# EFR32FG23B021F512IM48 register map
Vendor: Silicon Labs; Series: EFR32; File version: C
CPU: CM33 r0p4, little endian, MPU, FPU, DSP, VTOR, 4 interrupt priority bits, 8 SAU regions
Registers are 32-bit, read-write, reset 0x0 unless marked. A register's access mark holds for its fields unless they carry their own. Offsets are from the block's base; [hi:lo] are bit positions; {n}, {i} and the like mark numbered series; 'fields as' and 'values as' point back to an identical list.

## LESENSE_NS — LESENSE_NS Registers
Base 0x59038000
Same registers: LESENSE_S 0x49038000
0x00 IPVERSION ro reset 0x1
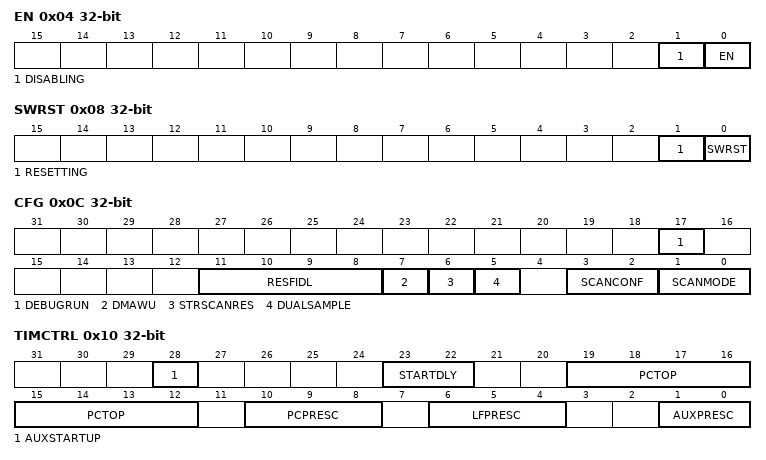
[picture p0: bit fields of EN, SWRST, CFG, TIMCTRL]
0x04 EN — Global Enable of LESENSE functions
  [1] DISABLING ro
  [0] EN — Enable
    0=DISABLE; 1=ENABLE
0x08 SWRST
  [1] RESETTING ro — Software reset busy status
  [0] SWRST wo — Software reset command
0x0C CFG — Configuration Register
  [17] DEBUGRUN — Debug Mode Run Enable
    0=LESENSE can not start new scans in debug mode; 1=LESENSE can start new scans in debug mode
  [11:8] RESFIDL — Result FIFO level
  [7] DMAWU — DMA wake-up from EM2
    0=DISABLE (No DMA wake-up from EM2); 1=ENABLE (DMA wake-up from EM2 when FIFO count is greater or equal to RESFIDL)
  [6] STRSCANRES — Enable storing of SCANRES
  [5] DUALSAMPLE — Enable dual sample mode
  [3:2] SCANCONF — Select scan configuration
    0=DIRMAP (The channel configuration register registers used are directly mapped to the channel number.); 1=INVMAP (The channel configuration registers used are CH[X+8]_CONF for channels 0-7 and CH[X-8]_CONF for channels 8-15.); 2=TOGGLE (The channel configuration registers used toggle between CH[X]_CONF and CH[X+8]_CONF when channel x triggers); 3=DECDEF (The decoder state defines the CONF registers to be used.)
  [1:0] SCANMODE — Configure scan mode
    0=PERIODIC (A new scan is started each time the period counter overflows); 1=ONESHOT (A single scan is performed when START in CMD is set); 2=PRS (Pulse on PRS channel)
0x10 TIMCTRL — Timing Control Register
  [28] AUXSTARTUP — AUX startup config
    0=PREDEMAND (Request oscillator .5 LESENSECLK cycle before sensing starts); 1=ONDEMAND (Request oscillator at sensing time)
  [23:22] STARTDLY — Start delay configuration
  [19:12] PCTOP — Period counter top value
  [10:8] PCPRESC — Period counter prescaling
    0=DIV1 (The period counter clock frequency is LESENSECLK/1); 1=DIV2 (The period counter clock frequency is LESENSECLK/2); 2=DIV4 (The period counter clock frequency is LESENSECLK/4); 3=DIV8 (The period counter clock frequency is LESENSECLK/8); 4=DIV16 (The period counter clock frequency is LESENSECLK/16); 5=DIV32 (The period counter clock frequency is LESENSECLK/32); 6=DIV64 (The period counter clock frequency is LESENSECLK/64); 7=DIV128 (The period counter clock frequency is LESENSECLK/128)
  [6:4] LFPRESC — Prescaling factor for low frequency time
    0=DIV1 (Low frequency timer is clocked with LESENSECLK/1); 1=DIV2 (Low frequency timer is clocked with LESENSECLK/2); 2=DIV4 (Low frequency timer is clocked with LESENSECLK/4); 3=DIV8 (Low frequency timer is clocked with LESENSECLK/8); 4=DIV16 (Low frequency timer is clocked with LESENSECLK/16); 5=DIV32 (Low frequency timer is clocked with LESENSECLK/32); 6=DIV64 (Low frequency timer is clocked with LESENSECLK/64); 7=DIV128 (Low frequency timer is clocked with LESENSECLK/128)
  [1:0] AUXPRESC — Prescaling factor for high frequency tim
    0=DIV1 (High frequency timer is clocked at LESENSEHFCLK/1); 1=DIV2 (High frequency timer is clocked at LESENSEHFCLK/2); 2=DIV4 (High frequency timer is clocked at LESENSEHFCLK/4); 3=DIV8 (High frequency timer is clocked at LESENSEHFCLK/8)
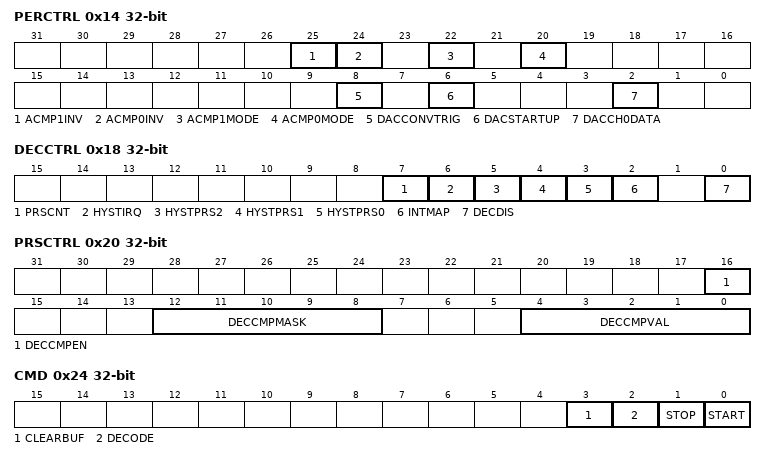
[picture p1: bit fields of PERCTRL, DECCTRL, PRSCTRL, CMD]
0x14 PERCTRL — Peripheral Control Register
  [25] ACMP1INV — Invert analog comparator 1 output
  [24] ACMP0INV — Invert analog comparator 0 output
  [22] ACMP1MODE
    0=MUX (LESENSE controls the POSSEL of ACMP1); 1=MUXTHRES (LESENSE POSSEL and reference divider of ACMP1)
  [20] ACMP0MODE
    0=MUX (LESENSE controls POSSEL of ACMP0); 1=MUXTHRES (LESENSE controls POSSEL and reference divider of ACMP0)
  [8] DACCONVTRIG — DAC conversion trigger configuration
    0=CHANNELSTART (DAC is enabled before every LESENSE channle measurement.); 1=SCANSTART (DAC is only enabled once per scan.)
  [6] DACSTARTUP — DAC startup configuration
    0=FULLCYCLE (DAC is started a full LESENSECLK before sensor interaction starts.); 1=HALFCYCLE (DAC is started half a LESENSECLK cycle before sensor interaction starts.)
  [2] DACCH0DATA — DAC CH0 data selection.
    0=DACDATA (DAC data is defined by CH0DATA in the DAC interface.); 1=THRES (DAC data is defined by THRES in CHx_INTERACT.)
0x18 DECCTRL — Decoder control Register
  [7] PRSCNT — Enable count mode on decoder PRS channel
  [6] HYSTIRQ — Enable decoder hysteresis on interrupt r
  [5] HYSTPRS2 — Enable decoder hysteresis on PRS2 output
  [4] HYSTPRS1 — Enable decoder hysteresis on PRS1 output
  [3] HYSTPRS0 — Enable decoder hysteresis on PRS0 output
  [2] INTMAP — Enable decoder to channel interrupt map
  [0] DECDIS — Disable the decoder
0x1C EVALCTRL — LESENSE evaluation control
  [15:0] WINSIZE — Sliding window and step detection size
0x20 PRSCTRL — PRS control register
  [16] DECCMPEN — Enable PRS output DECCMP
  [12:8] DECCMPMASK — Decoder state compare value mask
  [4:0] DECCMPVAL — Decoder state compare value
0x24 CMD wo — Command Register
  [3] CLEARBUF — Clear result buffer
  [2] DECODE — Start decoder
  [1] STOP — Stop scanning of sensors
  [0] START — Start scanning of sensors.
0x28 CHEN — Channel enable Register
  [15:0] CHEN — Enable scan channel
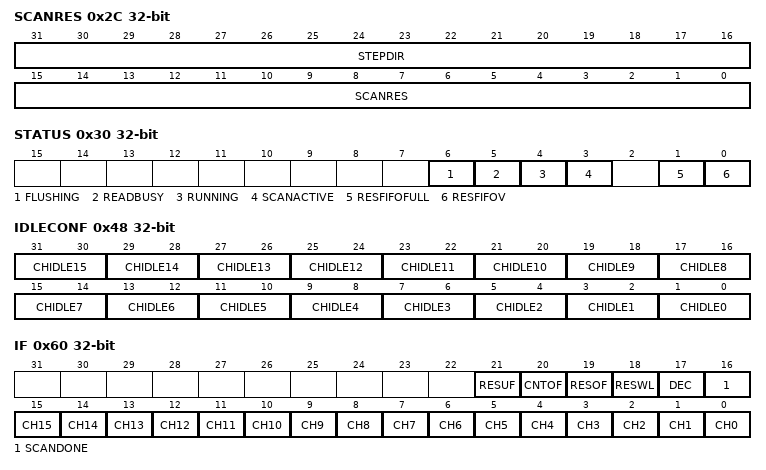
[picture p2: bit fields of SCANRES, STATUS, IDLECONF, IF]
0x2C SCANRES ro — Scan result register
  [31:16] STEPDIR — Direction of previous step detection
  [15:0] SCANRES — Scan results
0x30 STATUS ro
  [6] FLUSHING — FIFO Flushing
  [5] READBUSY — FIFO Read Busy
  [4] RUNNING — LESENSE periodic counter running
  [3] SCANACTIVE — LESENSE scan active
  [1] RESFIFOFULL — Result fifo full
  [0] RESFIFOV — Result fifo valid
0x34 RESCOUNT ro — Result FIFO Count
  [4:0] COUNT — Result Fifo Count
0x38 RESFIFO ro — Result Fifo
  [19:0] BUFDATASRC — Result data and source
0x3C CURCH ro — Current channel index
  [3:0] CURCH — Shows the index of the current channel
0x40 DECSTATE ro — Current decoder state
  [4:0] DECSTATE — Shows the current decoder state
0x44 SENSORSTATE ro — Decoder input register
  [3:0] SENSORSTATE
0x48 IDLECONF — GPIO Idle phase configuration
  [all] fields
    0=DISABLE (Channel output is disabled in idle phase); 1=HIGH (Channel output is high in idle phase); 2=LOW (Channel output is low in idle phase); 3=DAC (Channel output is connected to DAC output in idle phase (CH 0,1,2 only))
  [2n+1:2n] CHIDLE{n} (n=0..15) — Channel IDLE configuration
0x50 SYNCBUSY ro — Synchronization Busy Register
  [0] CMD — Command
0x60 IF — Interrupt Flags
  [21] RESUF — Result Underflow
  [20] CNTOF — Counter Overflow
  [19] RESOF — Result Overflow
  [18] RESWL — Result Watermark Level
  [17] DEC — Decoder
  [16] SCANDONE
  [n] CH{n} (n=0..15) — Channel
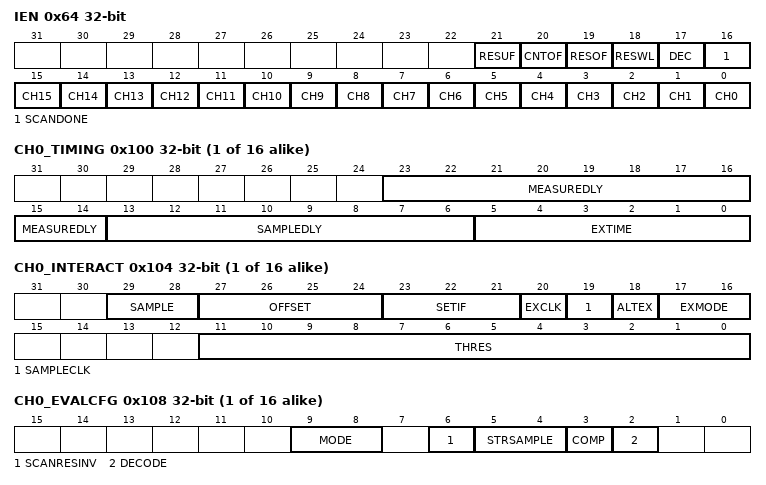
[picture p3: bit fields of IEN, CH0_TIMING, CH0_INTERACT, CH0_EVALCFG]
0x64 IEN — Interrupt Enables
  [21] RESUF — Result Underflow
  [20] CNTOF — Counter Overflow
  [19] RESOF — Result Overflow
  [18] RESWL — Result Watermark Level
  [17] DEC — Decoder
  [16] SCANDONE — Scan Complete
  [n] CH{n} (n=0..15) — Channel
{0x100+0x10*i} CH{i}_TIMING (i=0..15)
  [23:14] MEASUREDLY — Set measure delay
  [13:6] SAMPLEDLY — Set sample delay
  [5:0] EXTIME — Set excitation time
{0x104+0x10*i} CH{i}_INTERACT (i=0..15)
  [29:28] SAMPLE — Sample mode Selection
    0=ACMPCOUNT; 1=ACMP; 2=ADC; 3=ADCDIFF
  [27:24] OFFSET — OFFSET for IADC/ACMP interaction
  [23:21] SETIF — Enable interrupt generation
    0=NONE (No interrupt is generated); 1=LEVEL (Set interrupt flag if the sensor triggers.); 2=POSEDGE (Set interrupt flag on positive edge of the sensor state); 3=NEGEDGE (Set interrupt flag on negative edge of the sensor state); 4=BOTHEDGES (Set interrupt flag on both edges of the sensor state)
  [20] EXCLK — Select clock used for excitation timing
    0=LFACLK (Prescaled low-frequency LESENSECLK will be used for timing); 1=AUXHFRCO (Prescaled high-frequency LESENSEHFCLK will be used for timing)
  [19] SAMPLECLK — Select clock used for timing of sample d
    values as EXCLK
  [18] ALTEX — Use alternative excite pin
  [17:16] EXMODE — Set GPIO mode
    0=DISABLE (Disabled); 1=HIGH (Push Pull, GPIO is driven high); 2=LOW (Push Pull, GPIO is driven low); 3=DACOUT (DAC output)
  [11:0] THRES — ACMP threshold or DAC data
{0x108+0x10*i} CH{i}_EVALCFG (i=0..15)
  [9:8] MODE — Configure evaluation mode
    0=THRES (Threshold comparison is used to evaluate sensor result); 1=SLIDINGWIN (Sliding window is used to evaluate sensor result); 2=STEPDET (Step detection is used to evaluate sensor result)
  [6] SCANRESINV — Enable inversion of result
  [5:4] STRSAMPLE — Enable storing of sensor sample in resul
    0=DISABLE (Nothing will be stored in the result buffer.); 1=DATA (The sensor sample data will be stored in the result buffer.); 2=DATASRC (The data source, i.e. the channel, will be stored alongside the sensor sample data.)
  [3] COMP — Select mode for threshold comparison
    0=LESS (Comparison evaluates to 1 if sensor data is less than CTRTHRESHOLD, or if the ACMP output is 0); 1=GE (Comparison evaluates to 1 if sensor data is greater than, or equal to CTRTHRESHOLD, or if the ACMP output is 1)
  [2] DECODE — Send result to decoder
{0x10C+0x10*i} CH{i}_EVALTHRES (i=0..15)
  [15:0] EVALTHRES — Threshold
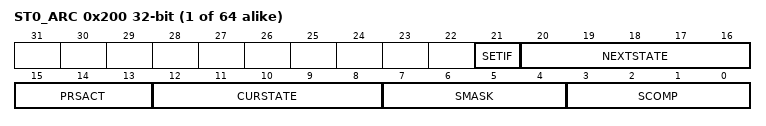
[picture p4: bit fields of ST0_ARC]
{0x200+4i} ST{i}_ARC (i=0..63)
  [21] SETIF — Set interrupt flag
  [20:16] NEXTSTATE — Next state index
  [15:13] PRSACT — Configure transition action in normal mode
    0=NONE (No PRS output generated (if PRSCOUNT == 0), or do not count (if PRSCOUNT == 1).); 1=PRS0 (Pulse generated on LESENSE PRS output 0 (if PRSCOUNT == 0).); 1=UP (Count Up (if PRSCOUNT == 1).); 2=PRS1 (Pulse generated on LESENSE PRS output 1 (if PRSCOUNT == 0).); 2=DOWN (Count Down (if PRSCOUNT == 1).); 3=PRS01 (Pulse generated on LESENSE PRS output 0 and 1 (if PRSCOUNT == 0).); 4=PRS2 (Pulse generated on LESENSE PRS output 2. (PRSCOUNT == 0 OR 1).); 5=PRS02 (Pulse generated on LESENSE PRS output 0 and 2 (if PRSCOUNT == 0).); 5=UPANDPRS2 (Count Up and Pulse generated on LESENSE PRS output 2 (if PRSCOUNT == 1).); 6=PRS12 (Pulse generated on LESENSE PRS output 1 and 2 (if PRSCOUNT == 0).); 6=DOWNANDPRS2 (Count Down and Pulse generated on LESENSE PRS output 2 (if PRSCOUNT == 1).); 7=PRS012 (Pulse generated on LESENSE PRS output 0, 1 and 2 (if PRSCOUNT == 0).)
  [12:8] CURSTATE — Current State
  [7:4] SMASK — Sensor mask
  [3:0] SCOMP — Sensor compare value
